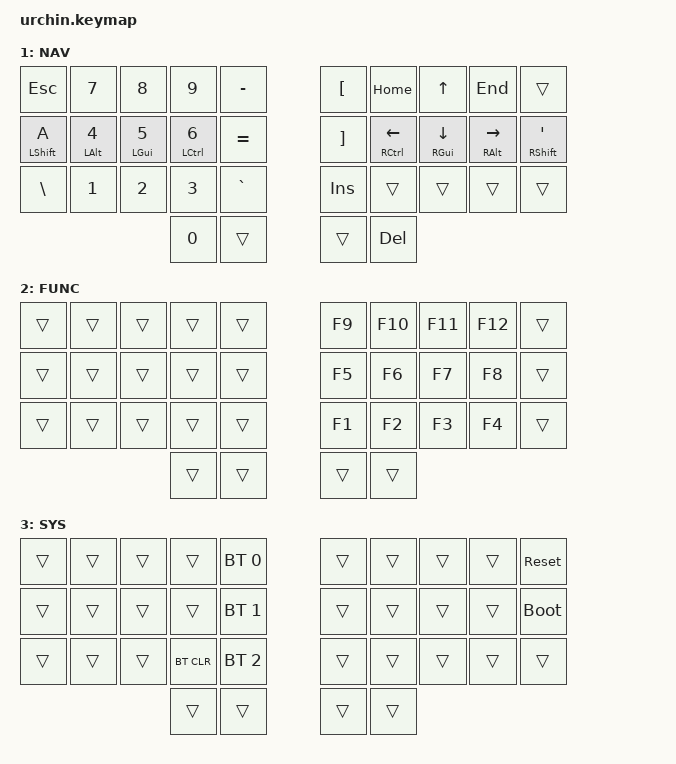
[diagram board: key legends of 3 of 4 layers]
#include <behaviors.dtsi>
#include <dt-bindings/zmk/keys.h>
#include <dt-bindings/zmk/bt.h>
#include <dt-bindings/zmk/outputs.h>

#define BASE 0
#define NAV  1
#define FUNC  2
#define SYS  3

// Home row mods macro
#define HRML(k1,k2,k3,k4) &ht LSHFT k1  &ht LALT k2  &ht LGUI k3  &ht LCTRL k4
#define HRMR(k1,k2,k3,k4) &ht LCTRL k1  &ht RGUI k2  &ht RALT k3  &ht RSHFT k4

/ {
    behaviors {
        ht: hold_tap {
            compatible = "zmk,behavior-hold-tap";
            #binding-cells = <2>;
            flavor = "balanced";
            quick-tap-ms = <125>;
            tapping-term-ms = <150>;
            bindings = <&kp>, <&kp>;
            hold-trigger-on-release;
            require-prior-idle-ms = <100>;
        };
    };

     combos {
        compatible = "zmk,combos";
        combo_ralt {
            timeout-ms = <50>;
            key-positions = <16 17>;
            bindings = <&kp RALT>;
        };
        combo_caps {
            timeout-ms = <50>;
            key-positions = <12 13>;
            bindings = <&kp CAPS>;
        };
    };

    conditional_layers {
        compatible = "zmk,conditional-layers";
        tri_layer {
            if-layers = <1 2>;
            then-layer = <3>;
        };
    };

    macros {
        langhold: langhold {
            compatible = "zmk,behavior-macro";
            label = "ZM_langhold";
            #binding-cells = <0>;
            bindings
            = <&macro_press &kp CAPS>
            , <&macro_pause_for_release>
            , <&macro_release &kp CAPS>
            ;
        };
    };

        keymap {
                compatible = "zmk,keymap";
// ▄▄▄▄▄▄▄▄▄▄▄▄▄▄▄▄▄▄▄▄▄▄▄▄▄▄▄▄▄▄▄▄▄▄▄▄▄▄▄▄▄▄▄▄▄▄▄▄▄▄▄▄▄▄▄▄▄▄▄▄▄▄▄▄▄▄▄▄▄▄▄▄▄▄▄▄▄▄▄▄▄▄▄▄▄▄▄▄▄▄▄▄▄▄▄▄▄▄▄▄▄▄▄▄▄▄▄▄▄▄▄▄▄▄▄▄▄▄▄▄▄▄▄▄▄▄▄▄▄▄▄▄▄▄▄▄▄▄▄▄▄▄▄▄▄▄▄▄▄

                base_layer {
// ┏━━━━━━━━━━━━━━━━━━━━━━━━━━━━━━━━━━━━━━━┓
label= "BASE"                              ;
// ┗━━━━━━━━━━━━━━━━━━━━━━━━━━━━━━━━━━━━━━━┛

 bindings = <
// ╷           ╷           ╷           ╷           ╷           ╷   ╷           ╷           ╷           ╷           ╷           ╷

    &kp Q       &kp W       &kp E       &kp R       &kp T           &kp Y       &kp U       &kp I       &kp O       &kp P
    HRML(A,     S,          D,          F)          &kp G           &kp H       HRMR(J,     K,          L,          SEMI)
    &kp Z       &kp X       &kp C       &kp V       &kp B           &kp N       &kp M       &kp COMMA   &kp DOT     &kp FSLH
                                        &ht LALT TAB  &lt 1 SPACE     &lt 1 ENTER &lt 2 BSPC
                        >;
                };

// ▄▄▄▄▄▄▄▄▄▄▄▄▄▄▄▄▄▄▄▄▄▄▄▄▄▄▄▄▄▄▄▄▄▄▄▄▄▄▄▄▄▄▄▄▄▄▄▄▄▄▄▄▄▄▄▄▄▄▄▄▄▄▄▄▄▄▄▄▄▄▄▄▄▄▄▄▄▄▄▄▄▄▄▄▄▄▄▄▄▄▄▄▄▄▄▄▄▄▄▄▄▄▄▄▄▄▄▄▄▄▄▄▄▄▄▄▄▄▄▄▄▄▄▄▄▄▄▄▄▄▄▄▄▄▄▄▄▄▄▄▄▄▄▄▄▄▄▄▄


                nav_layer {
// ┏━━━━━━━━━━━━━━━━━━━━━━━━━━━━━━━━━━━━━━━┓
label= "NAV"                              ;
// ┗━━━━━━━━━━━━━━━━━━━━━━━━━━━━━━━━━━━━━━━┛

 bindings = <
// ╷           ╷           ╷           ╷           ╷           ╷   ╷           ╷           ╷           ╷           ╷           ╷

    &kp ESC     &kp N7      &kp N8      &kp N9       &kp MINUS       &kp LBKT  &kp HOME       &kp UP        &kp END        &trans
    &mt LSHFT A &mt LALT N4 &mt LGUI N5 &mt LCTRL N6 &kp EQUAL       &kp RBKT  &mt RCTRL LEFT &mt RGUI DOWN &mt RALT RIGHT &mt RSHFT SQT
    &kp BSLH    &kp N1      &kp N2      &kp N3       &kp GRAVE       &kp INSERT &trans         &trans        &trans         &trans
                                        &kp N0       &trans          &trans    &kp DEL         
                        >;
                };

// ▄▄▄▄▄▄▄▄▄▄▄▄▄▄▄▄▄▄▄▄▄▄▄▄▄▄▄▄▄▄▄▄▄▄▄▄▄▄▄▄▄▄▄▄▄▄▄▄▄▄▄▄▄▄▄▄▄▄▄▄▄▄▄▄▄▄▄▄▄▄▄▄▄▄▄▄▄▄▄▄▄▄▄▄▄▄▄▄▄▄▄▄▄▄▄▄▄▄▄▄▄▄▄▄▄▄▄▄▄▄▄▄▄▄▄▄▄▄▄▄▄▄▄▄▄▄▄▄▄▄▄▄▄▄▄▄▄▄▄▄▄▄▄▄▄▄▄▄▄


                func_layer {
// ┏━━━━━━━━━━━━━━━━━━━━━━━━━━━━━━━━━━━━━━━┓
label= "FUNC"                               ;
// ┗━━━━━━━━━━━━━━━━━━━━━━━━━━━━━━━━━━━━━━━┛

 bindings = <
// ╷           ╷           ╷           ╷           ╷           ╷   ╷           ╷           ╷           ╷           ╷           ╷

    &trans     &trans       &trans       &trans      &trans         &kp F9      &kp F10     &kp F11      &kp F12     &trans       
    &trans     &trans       &trans       &trans      &trans         &kp F5      &kp F6      &kp F7       &kp F8      &trans 
    &trans     &trans       &trans       &trans      &trans         &kp F1      &kp F2      &kp F3       &kp F4      &trans
                                         &trans      &trans         &trans      &trans
                        >;
                };

// ▄▄▄▄▄▄▄▄▄▄▄▄▄▄▄▄▄▄▄▄▄▄▄▄▄▄▄▄▄▄▄▄▄▄▄▄▄▄▄▄▄▄▄▄▄▄▄▄▄▄▄▄▄▄▄▄▄▄▄▄▄▄▄▄▄▄▄▄▄▄▄▄▄▄▄▄▄▄▄▄▄▄▄▄▄▄▄▄▄▄▄▄▄▄▄▄▄▄▄▄▄▄▄▄▄▄▄▄▄▄▄▄▄▄▄▄▄▄▄▄▄▄▄▄▄▄▄▄▄▄▄▄▄▄▄▄▄▄▄▄▄▄▄▄▄▄▄▄▄


                sys_layer {
// ┏━━━━━━━━━━━━━━━━━━━━━━━━━━━━━━━━━━━━━━━┓
label= "SYS"                               ;
// ┗━━━━━━━━━━━━━━━━━━━━━━━━━━━━━━━━━━━━━━━┛

 bindings = <
// ╷           ╷           ╷           ╷           ╷           ╷   ╷           ╷           ╷           ╷           ╷           ╷

    &trans     &trans       &trans       &trans      &bt BT_SEL 0   &trans      &trans      &trans       &trans      &sys_reset       
    &trans     &trans       &trans       &trans      &bt BT_SEL 1   &trans      &trans      &trans       &trans      &bootloader 
    &trans     &trans       &trans       &bt BT_CLR  &bt BT_SEL 2   &trans      &trans      &trans       &trans      &trans
                                         &trans      &trans         &trans      &trans      
                        >;
                };

// ▄▄▄▄▄▄▄▄▄▄▄▄▄▄▄▄▄▄▄▄▄▄▄▄▄▄▄▄▄▄▄▄▄▄▄▄▄▄▄▄▄▄▄▄▄▄▄▄▄▄▄▄▄▄▄▄▄▄▄▄▄▄▄▄▄▄▄▄▄▄▄▄▄▄▄▄▄▄▄▄▄▄▄▄▄▄▄▄▄▄▄▄▄▄▄▄▄▄▄▄▄▄▄▄▄▄▄▄▄▄▄▄▄▄▄▄▄▄▄▄▄▄▄▄▄▄▄▄▄▄▄▄▄▄▄▄▄▄▄▄▄▄▄▄▄▄▄▄▄

         };
};
